# STM32G554 register map
File version: 2.0.0
CPU: CM33 r0p4, little endian, MPU, FPU, 4 interrupt priority bits
Registers are 32-bit, read-write, reset 0x0 unless marked. A register's access mark holds for its fields unless they carry their own. Offsets are from the block's base; [hi:lo] are bit positions; {n}, {i} and the like mark numbered series.

## DBGMCU — DBGMCU register block
Base 0x44026000
Same registers: DBGMCU_S 0x54026000
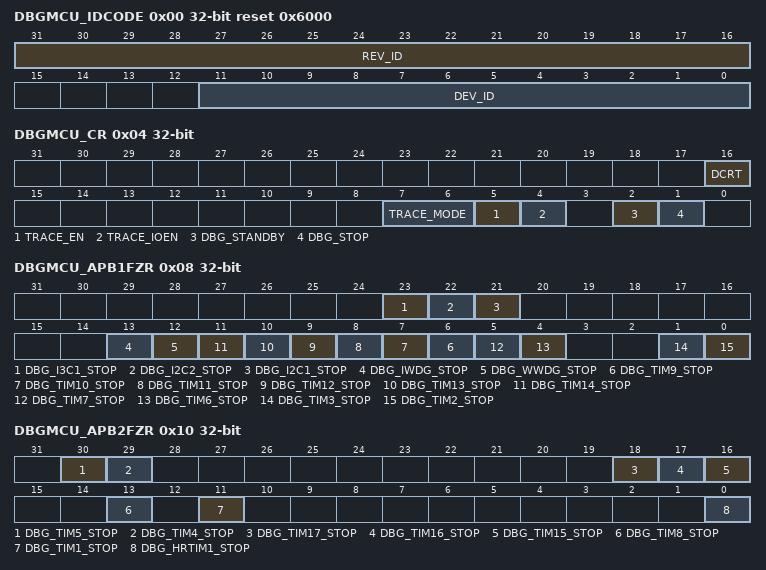
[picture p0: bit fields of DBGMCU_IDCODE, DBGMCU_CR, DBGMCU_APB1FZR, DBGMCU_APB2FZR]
0x00 DBGMCU_IDCODE ro reset 0x6000 (reset mask 0xF000) — DBGMCU identity code register
  [31:16] REV_ID — Revision
  [11:0] DEV_ID — Device identification
    0x44A=STM32G55x/56x; 0x44B=STM32G53x/54x
0x04 DBGMCU_CR — DBGMCU configuration register
  [16] DCRT — Debug credentials reset type
    0=System reset; 1=Power reset
  [7:6] TRACE_MODE — trace pin assignment
    0=trace pins assigned for asynchronous mode (TRACESWO); 1=trace pins assigned for synchronous mode with a port width of 1 (TRACECK, TRACED0); 2=trace pins assigned for synchronous mode with a port width of 2 ((TRACECK, TRACED0-1); 3=trace pins assigned for synchronous mode with a port width of 4 ((TRACECK, TRACED0-3)
  [5] TRACE_EN — trace port and clock enable.
    0=disabled; 1=enabled
  [4] TRACE_IOEN — trace pin enable
    0=disabled - trace pins not assigned; 1=enabled - trace pins assigned according to the value of TRACE_MODE field
  [2] DBG_STANDBY — Allows debug in Standby mode
    0=normal operation; 1=automatic clock stop/power down disabled
  [1] DBG_STOP — Allows debug in Stop mode
    0=normal operation; 1=automatic clock stop disabled
0x08 DBGMCU_APB1FZR — DBGMCU APB1 peripheral freeze register
  [23] DBG_I3C1_STOP — I3C1 SCL stall counter stop in debug
    0=normal operation. I3C1 SCL stall timeout counter continues to operate while CPU is in debug mode.; 1=stop in debug. I3C1 SCL stall timeout counter is frozen while CPU is in debug mode.
  [22] DBG_I2C2_STOP — I2C2 SMBUS timeout stop in debug
    0=normal operation. I2C2 SMBUS timeout continues to operate while CPU is in debug mode.; 1=stop in debug. I2C2 SMBUS timeout is frozen while CPU is in debug mode.
  [21] DBG_I2C1_STOP — I2C1 SMBUS timeout stop in debug
    0=normal operation. I2C1 SMBUS timeout continues to operate while CPU is in debug mode.; 1=stop in debug. I2C1 SMBUS timeout is frozen while CPU is in debug mode.
  [13] DBG_IWDG_STOP — IWDG stop in debug
    0=normal operation. IWDG continues to operate while CPU is in debug mode.; 1=stop in debug. IWDG is frozen while CPU is in debug mode.
  [12] DBG_WWDG_STOP — WWDG stop in debug
    0=normal operation. WWDG continues to operate while CPU is in debug mode.; 1=stop in debug. WWDG is frozen while CPU is in debug mode.
  [n-3] DBG_TIM{n}_STOP (n=9..14) — TIM{n} stop in debug
    0=normal operation. TIM{n} continues to operate while CPU is in debug mode.; 1=stop in debug. TIM{n} is frozen while CPU is in debug mode.
  [5] DBG_TIM7_STOP — TIM7 stop in debug
    0=normal operation. TIM7 continues to operate while CPU is in debug mode.; 1=stop in debug. TIM7 is frozen while CPU is in debug mode.
  [4] DBG_TIM6_STOP — TIM6 stop in debug
    0=normal operation. TIM6 continues to operate while CPU is in debug mode.; 1=stop in debug. TIM6 is frozen while CPU is in debug mode.
  [1] DBG_TIM3_STOP — TIM3 stop in debug
    0=normal operation. TIM3 continues to operate while CPU is in debug mode.; 1=stop in debug. TIM3 is frozen while CPU is in debug mode.
  [0] DBG_TIM2_STOP — TIM2 stop in debug
    0=normal operation. TIM2 continues to operate while CPU is in debug mode.; 1=stop in debug. TIM2 is frozen while CPU is in debug mode.
0x10 DBGMCU_APB2FZR — DBGMCU APB2 peripheral freeze register
  [30] DBG_TIM5_STOP — TIM5 stop in debug
    0=normal operation. TIM5 continues to operate while CPU is in debug mode.; 1=Stop in debug. TIM5 is frozen while CPU is in debug mode.
  [29] DBG_TIM4_STOP — TIM4 stop in debug
    0=normal operation. TIM4 continues to operate while CPU is in debug mode.; 1=stop in debug. TIM4 is frozen while CPU is in debug mode.
  [18] DBG_TIM17_STOP — TIM17 stop in debug
    0=normal operation. TIM17 continues to operate while CPU is in debug mode.; 1=stop in debug. TIM17 is frozen while CPU is in debug mode.
  [17] DBG_TIM16_STOP — TIM16 stop in debug
    0=normal operation. TIM16 continues to operate while CPU is in debug mode.; 1=stop in debug. TIM16 is frozen while CPU is in debug mode.
  [16] DBG_TIM15_STOP — TIM15 stop in debug
    0=normal operation. TIM15 continues to operate while CPU is in debug mode.; 1=stop in debug. TIM15 is frozen while CPU is in debug mode.
  [13] DBG_TIM8_STOP — TIM8 stop in debug
    0=normal operation. TIM8 continues to operate while CPU is in debug mode.; 1=stop in debug. TIM8 is frozen while CPU is in debug mode.
  [11] DBG_TIM1_STOP — TIM1 stop in debug
    0=normal operation. TIM1 continues to operate while CPU is in debug mode.; 1=stop in debug. TIM1 is frozen while CPU is in debug mode.
  [0] DBG_HRTIM1_STOP — HRTIM1 stop in debug
    0=normal operation. HRTIM1 continues to operate while CPU is in debug mode.; 1=stop in debug. HRTIM1 is frozen while CPU is in debug mode.
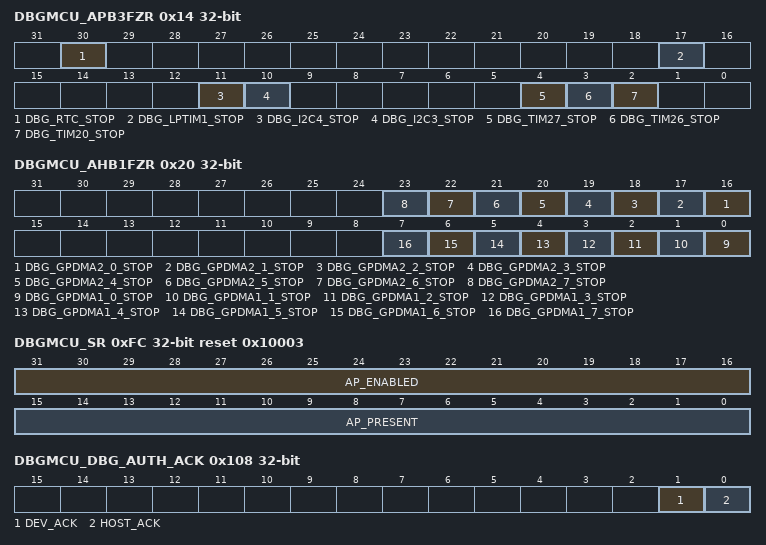
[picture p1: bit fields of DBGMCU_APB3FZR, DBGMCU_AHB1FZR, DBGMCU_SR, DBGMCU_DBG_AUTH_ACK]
0x14 DBGMCU_APB3FZR — DBGMCU APB3 peripheral freeze register
  [30] DBG_RTC_STOP — RTC stop in debug
    0=normal operation. RTC continues to operate while CPU is in debug mode.; 1=stop in debug. RTC is frozen while CPU is in debug mode.
  [17] DBG_LPTIM1_STOP — LPTIM1 stop in debug
    0=normal operation. LPTIM1 continues to operate while CPU is in debug mode.; 1=stop in debug. LPTIM1 is frozen while CPU is in debug mode.
  [11] DBG_I2C4_STOP — I2C4 SMBUS timeout stop in debug
    0=normal operation. I2C4 SMBUS timeout counter continues to operate while CPU is in debug mode.; 1=stop in debug. I2C4 SMBUS timeout counter is frozen while CPU is in debug mode.
  [10] DBG_I2C3_STOP — I2C3 SMBUS timeout stop in debug
    0=normal operation. I2C3 SMBUS timeout counter continues to operate while CPU is in debug mode.; 1=stop in debug. I2C3 SMBUS timeout counter is frozen while CPU is in debug mode.
  [4] DBG_TIM27_STOP — TIM27 stop in debug
    0=normal operation. TIM27 continues to operate while CPU is in debug mode.; 1=stop in debug. TIM27 is frozen while CPU is in debug mode.
  [3] DBG_TIM26_STOP — TIM26 stop in debug
    0=normal operation. TIM26 continues to operate while CPU is in debug mode.; 1=stop in debug. TIM26 is frozen while CPU is in debug mode.
  [2] DBG_TIM20_STOP — TIM20 stop in debug
    0=normal operation. TIM20 continues to operate while CPU is in debug mode.; 1=stop in debug. TIM20 is frozen while CPU is in debug mode.
0x20 DBGMCU_AHB1FZR — DBGMCU AHB1 peripheral freeze register
  [n+16] DBG_GPDMA2_{n}_STOP (n=0..7) — GPDMA2 channel {n} stop in debug
    0=normal operation. GPDMA2 channel {n} continues to operate while CPU is in debug mode.; 1=stop in debug. GPDMA2 channel {n} is frozen while CPU is in debug mode.
  [n] DBG_GPDMA1_{n}_STOP (n=0..7) — GPDMA1 channel {n} stop in debug
    0=normal operation. GPDMA1 channel {n} continues to operate while CPU is in debug mode.; 1=stop in debug. GPDMA1 channel {n} is frozen while CPU is in debug mode.
0x80 DBGMCU_EDBGRQ — DBGMCU EDBGRQ debug request control
  [0] DBG_CPU — drives the CPU external debug request (EDBGRQ) signal.
    0=External debug request de-asserted; 1=External debug request asserted
0xFC DBGMCU_SR ro reset 0x10003 (reset mask 0xFFFF00FF) — DBGMCU status register
  [31:16] AP_ENABLED — Bit n identifies whether access port AP n is open (can be accessed via the debug port) or locked (debug access to the AP is blocked)
  [15:0] AP_PRESENT — Bit n identifies whether access port AP n is present in device
0x100 DBGMCU_DBG_AUTH_HOST reset not defined — DBGMCU debug authentication mailbox host register
  [31:0] MESSAGE — Debug host to device mailbox message.
0x104 DBGMCU_DBG_AUTH_DEVICE reset not defined — DBGMCU debug authentication mailbox device register
  [31:0] MESSAGE — Device to debug host mailbox message.
0x108 DBGMCU_DBG_AUTH_ACK ro — DBGMCU debug authentication mailbox acknowledge register
  [1] DEV_ACK — Device to host acknowledge.
    0=DBGMCU_DBG_AUTH_DEVICE register is empty
  [0] HOST_ACK — Host to device acknowledge.
    0=DBGMCU_DBG_AUTH_HOST register is empty
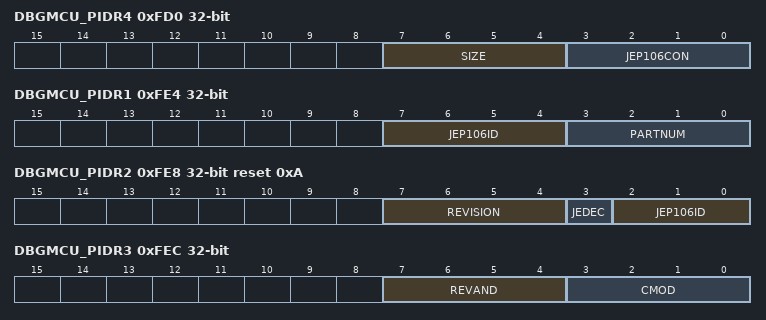
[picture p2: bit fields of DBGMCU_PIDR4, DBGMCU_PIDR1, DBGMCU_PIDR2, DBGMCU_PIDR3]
0xFD0 DBGMCU_PIDR4 ro — DBGMCU CoreSight peripheral identity register 4
  [7:4] SIZE — register file size
    0=The register file occupies a single 4-Kbyte region
  [3:0] JEP106CON — JEP106 continuation code
    0=STMicroelectronics JEDEC code
0xFE0 DBGMCU_PIDR0 ro — DBGMCU CoreSight peripheral identity register 0
  [7:0] PARTNUM — part number bits [7:0]
    0=DBGMCU part number
0xFE4 DBGMCU_PIDR1 ro — DBGMCU CoreSight peripheral identity register 1
  [7:4] JEP106ID — JEP106 identity code bits [3:0]
    0=STMicroelectronics JEDEC code
  [3:0] PARTNUM — part number bits [11:8]
    0=DBGMCU part number
0xFE8 DBGMCU_PIDR2 ro reset 0xA — DBGMCU CoreSight peripheral identity register 2
  [7:4] REVISION — component revision number
    0=r0p0
  [3] JEDEC — JEDEC assigned value
    1=designer identification specified by JEDEC
  [2:0] JEP106ID — JEP106 identity code bits [6:4]
    2=STMicroelectronics JEDEC code
0xFEC DBGMCU_PIDR3 ro — DBGMCU CoreSight peripheral identity register 3
  [7:4] REVAND — metal fix version
    0=no metal fix
  [3:0] CMOD — customer modified
    0=no customer modifications
0xFF0 DBGMCU_CIDR0 ro reset 0xD — DBGMCU CoreSight CoreSight component identity register 0
  [7:0] PREAMBLE — component identification bits [7:0]
    13=common identification value
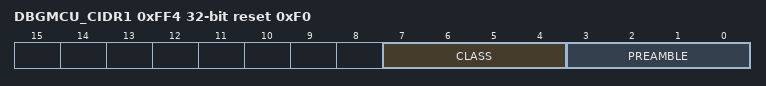
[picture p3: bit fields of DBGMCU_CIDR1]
0xFF4 DBGMCU_CIDR1 ro reset 0xF0 — DBGMCU CoreSight CoreSight component identity register 1
  [7:4] CLASS — component identification bits [15:12] - component class
    15=Non-CoreSight component
  [3:0] PREAMBLE — component identification bits [11:8]
    0=common identification value
0xFF8 DBGMCU_CIDR2 ro reset 0x5 — DBGMCU CoreSight CoreSight component identity register 2
  [7:0] PREAMBLE — component identification bits [23:16]
    5=common identification value
0xFFC DBGMCU_CIDR3 ro reset 0xB1 — DBGMCU CoreSight CoreSight component identity register 3
  [7:0] PREAMBLE — component identification bits [31:24]
    177=common identification value
